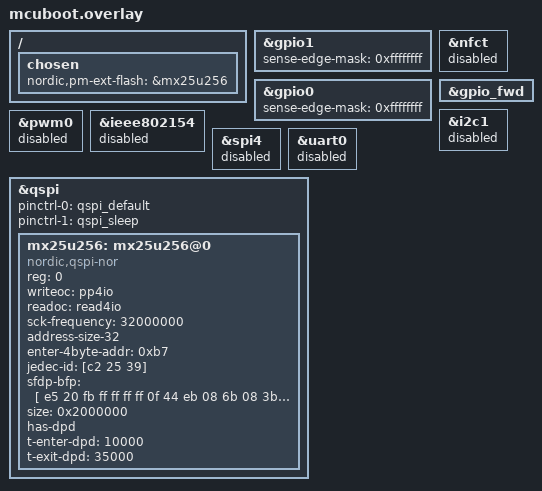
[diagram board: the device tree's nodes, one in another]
/* Add external flash to mcuboot */
/ {
	chosen {
		// nordic,pm-ext-flash = &mx25r64;
		nordic,pm-ext-flash = &mx25u256;
	};
	/delete-node/ aliases;
};


/delete-node/ &button0;
/delete-node/ &button1;
/delete-node/ &button2;
/delete-node/ &button3;
// /delete-node/ &buttons;
/delete-node/ &led0;
/delete-node/ &led1;
/delete-node/ &led2;
/delete-node/ &led3;
// /delete-node/ &leds;

&gpio1 {
	sense-edge-mask = <0xffffffff>;
};
&gpio0 {
	sense-edge-mask = <0xffffffff>;
};
&nfct {
	status = "disabled";
};
&gpio_fwd {
	// status = "disabled";// 将管脚控制权保留在应用核
	/delete-node/ uart;// 将管脚控制权保留在应用核
};

&i2c1 {
	status = "disabled";
};
&pwm0 {
	status = "disabled";
};
&ieee802154 {
	status = "disabled";
};
&spi4 {
	status = "disabled";
};
&uart0 {
	status = "disabled";
};

// &qspi {
// 	status = "okay";
// 	pinctrl-0 = <&qspi_default>;
// 	pinctrl-1 = <&qspi_sleep>;
// 	pinctrl-names = "default", "sleep";
// 	mx25r64: mx25r6435f@0 {
// 		compatible = "nordic,qspi-nor";
// 		reg = <0>;
// 		/* MX25R64 supports only pp and pp4io */
// 		writeoc = "pp4io";
// 		/* MX25R64 supports all readoc options */
// 		readoc = "read4io";
// 		sck-frequency = <32000000>;
// 		jedec-id = [c2 28 17];
// 		sfdp-bfp = [
// 			e5 20 f1 ff  ff ff ff 03  44 eb 08 6b  08 3b 04 bb
// 			ee ff ff ff  ff ff 00 ff  ff ff 00 ff  0c 20 0f 52
// 			10 d8 00 ff  23 72 f5 00  82 ed 04 cc  44 83 68 44
// 			30 b0 30 b0  f7 c4 d5 5c  00 be 29 ff  f0 d0 ff ff
// 		];
// 		size = <67108864>;
// 		has-dpd;
// 		t-enter-dpd = <10000>;
// 		t-exit-dpd = <35000>;
// 	};
// };

/delete-node/ &mx25r64;
&qspi {
	status = "okay";
	pinctrl-0 = <&qspi_default>;
	pinctrl-1 = <&qspi_sleep>;
	pinctrl-names = "default", "sleep";
	mx25u256: mx25u256@0 {
		compatible = "nordic,qspi-nor";
		reg = <0>;
		/* MX25U256 supports only pp and pp4io */
		writeoc = "pp4io";
		/* MX25U256 supports all readoc options */
		readoc = "read4io";
		sck-frequency = <32000000>;
		address-size-32;
		enter-4byte-addr = <0xb7>;
		jedec-id = [c2 25 39];
		sfdp-bfp = [
			e5 20 fb ff ff ff ff 0f  44 eb 08 6b 08 3b 04 bb
			fe ff ff ff ff ff 00 ff  ff ff 44 eb 0c 20 0f 52
			10 d8 00 ff 25 52 dd 00  84 a5 04 e2 44 03 17 38
			30 b0 30 b0 f7 bd d5 5c  4a 9e 29 ff f0 50 f9 85
		];
		size = <0x2000000>;
		has-dpd;
		t-enter-dpd = <10000>;
		t-exit-dpd = <35000>;
	};
};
